# ATSAM3S1B device description
Architecture: CORTEX-M3; Family: SAM3; Series: SAM3S
Registers are 32-bit, read-write, no defined reset value unless marked. A register's access mark holds for its fields unless they carry their own. Offsets are from the block's base; [hi:lo] are bit positions; {n}, {i} and the like mark numbered series; 'fields as' and 'values as' point back to an identical list.

## USART — Universal Synchronous Asynchronous Receiver Transmitter
Instances: USART0 0x40024000, USART1 0x40028000
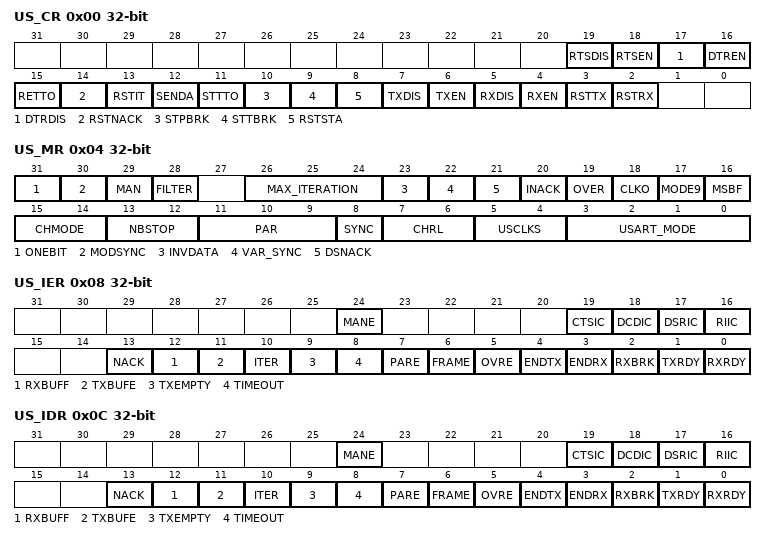
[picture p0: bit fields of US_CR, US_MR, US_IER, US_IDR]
0x00 US_CR wo — Control Register
  [19] RTSDIS — Request to Send Disable
  [18] RTSEN — Request to Send Enable
  [17] DTRDIS — Data Terminal Ready Disable
  [16] DTREN — Data Terminal Ready Enable
  [15] RETTO — Rearm Time-out
  [14] RSTNACK — Reset Non Acknowledge
  [13] RSTIT — Reset Iterations
  [12] SENDA — Send Address
  [11] STTTO — Start Time-out
  [10] STPBRK — Stop Break
  [9] STTBRK — Start Break
  [8] RSTSTA — Reset Status Bits
  [7] TXDIS — Transmitter Disable
  [6] TXEN — Transmitter Enable
  [5] RXDIS — Receiver Disable
  [4] RXEN — Receiver Enable
  [3] RSTTX — Reset Transmitter
  [2] RSTRX — Reset Receiver
0x04 US_MR — Mode Register
  [31] ONEBIT — Start Frame Delimiter Selector
  [30] MODSYNC — Manchester Synchronization Mode
  [29] MAN — Manchester Encoder/Decoder Enable
  [28] FILTER — Infrared Receive Line Filter
  [26:24] MAX_ITERATION — Maximum Number of Automatic Iteration
  [23] INVDATA — Inverted Data
  [22] VAR_SYNC — Variable Synchronization of Command/Data Sync Start Frame Delimiter
  [21] DSNACK — Disable Successive NACK
  [20] INACK — Inhibit Non Acknowledge
  [19] OVER — Oversampling Mode
  [18] CLKO — Clock Output Select
  [17] MODE9 — 9-bit Character Length
  [16] MSBF — Bit Order
  [15:14] CHMODE — Channel Mode
    0=NORMAL (Normal Mode); 1=AUTOMATIC (Automatic Echo. Receiver input is connected to the TXD pin.); 2=LOCAL_LOOPBACK (Local Loopback. Transmitter output is connected to the Receiver Input.); 3=REMOTE_LOOPBACK (Remote Loopback. RXD pin is internally connected to the TXD pin.)
  [13:12] NBSTOP — Number of Stop Bits
    0=_1_BIT (1 stop bit); 1=_1_5_BIT (1.5 stop bit (SYNC = 0) or reserved (SYNC = 1)); 2=_2_BIT (2 stop bits)
  [11:9] PAR — Parity Type
    0=EVEN (Even parity); 1=ODD (Odd parity); 2=SPACE (Parity forced to 0 (Space)); 3=MARK (Parity forced to 1 (Mark)); 4=NO (No parity); 6=MULTIDROP (Multidrop mode)
  [8] SYNC — Synchronous Mode Select
  [7:6] CHRL — Character Length.
    {v}=_{v+5}_BIT (Character length is {v+5} bits) (v=0..3)
  [5:4] USCLKS — Clock Selection
    0=MCK (Master Clock MCK is selected); 1=DIV (Internal Clock Divided MCK/DIV (DIV=8) is selected); 3=SCK (Serial Clock SLK is selected)
  [3:0] USART_MODE — USART Mode of Operation
    0=NORMAL (Normal mode); 1=RS485; 2=HW_HANDSHAKING (Hardware Handshaking); 3=MODEM; 4=IS07816_T_0 (IS07816 Protocol: T = 0); 6=IS07816_T_1 (IS07816 Protocol: T = 1); 8=IRDA; 14=SPI_MASTER; 15=SPI_SLAVE
0x08 US_IER wo — Interrupt Enable Register
  [24] MANE — Manchester Error Interrupt Enable
  [19] CTSIC — Clear to Send Input Change Interrupt Enable
  [18] DCDIC — Data Carrier Detect Input Change Interrupt Enable
  [17] DSRIC — Data Set Ready Input Change Enable
  [16] RIIC — Ring Indicator Input Change Enable
  [13] NACK — Non AcknowledgeInterrupt Enable
  [12] RXBUFF — Buffer Full Interrupt Enable (available in all USART modes of operation)
  [11] TXBUFE — Buffer Empty Interrupt Enable (available in all USART modes of operation)
  [10] ITER — Max number of Repetitions Reached Interrupt Enable
  [9] TXEMPTY — TXEMPTY Interrupt Enable
  [8] TIMEOUT — Time-out Interrupt Enable
  [7] PARE — Parity Error Interrupt Enable
  [6] FRAME — Framing Error Interrupt Enable
  [5] OVRE — Overrun Error Interrupt Enable
  [4] ENDTX — End of Transmit Interrupt Enable (available in all USART modes of operation)
  [3] ENDRX — End of Receive Transfer Interrupt Enable (available in all USART modes of operation)
  [2] RXBRK — Receiver Break Interrupt Enable
  [1] TXRDY — TXRDY Interrupt Enable
  [0] RXRDY — RXRDY Interrupt Enable
0x0C US_IDR wo — Interrupt Disable Register
  [24] MANE — Manchester Error Interrupt Disable
  [19] CTSIC — Clear to Send Input Change Interrupt Disable
  [18] DCDIC — Data Carrier Detect Input Change Interrupt Disable
  [17] DSRIC — Data Set Ready Input Change Disable
  [16] RIIC — Ring Indicator Input Change Disable
  [13] NACK — Non AcknowledgeInterrupt Disable
  [12] RXBUFF — Buffer Full Interrupt Disable (available in all USART modes of operation)
  [11] TXBUFE — Buffer Empty Interrupt Disable (available in all USART modes of operation)
  [10] ITER — Max Number of Repetitions Reached Interrupt Disable
  [9] TXEMPTY — TXEMPTY Interrupt Disable
  [8] TIMEOUT — Time-out Interrupt Disable
  [7] PARE — Parity Error Interrupt Disable
  [6] FRAME — Framing Error Interrupt Disable
  [5] OVRE — Overrun Error Interrupt Enable
  [4] ENDTX — End of Transmit Interrupt Disable (available in all USART modes of operation)
  [3] ENDRX — End of Receive Transfer Interrupt Disable (available in all USART modes of operation)
  [2] RXBRK — Receiver Break Interrupt Disable
  [1] TXRDY — TXRDY Interrupt Disable
  [0] RXRDY — RXRDY Interrupt Disable
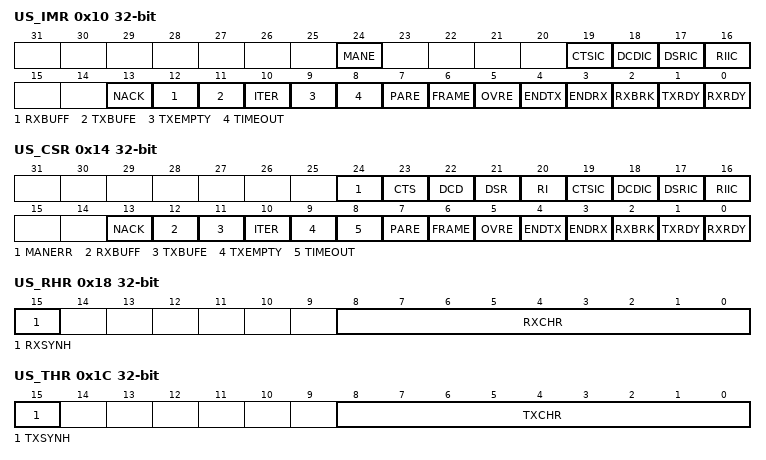
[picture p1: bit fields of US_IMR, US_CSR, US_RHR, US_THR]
0x10 US_IMR ro — Interrupt Mask Register
  [24] MANE — Manchester Error Interrupt Mask
  [19] CTSIC — Clear to Send Input Change Interrupt Mask
  [18] DCDIC — Data Carrier Detect Input Change Interrupt Mask
  [17] DSRIC — Data Set Ready Input Change Mask
  [16] RIIC — Ring Indicator Input Change Mask
  [13] NACK — Non AcknowledgeInterrupt Mask
  [12] RXBUFF — Buffer Full Interrupt Mask (available in all USART modes of operation)
  [11] TXBUFE — Buffer Empty Interrupt Mask (available in all USART modes of operation)
  [10] ITER — Max Number of Repetitions Reached Interrupt Mask
  [9] TXEMPTY — TXEMPTY Interrupt Mask
  [8] TIMEOUT — Time-out Interrupt Mask
  [7] PARE — Parity Error Interrupt Mask
  [6] FRAME — Framing Error Interrupt Mask
  [5] OVRE — Overrun Error Interrupt Mask
  [4] ENDTX — End of Transmit Interrupt Mask (available in all USART modes of operation)
  [3] ENDRX — End of Receive Transfer Interrupt Mask (available in all USART modes of operation)
  [2] RXBRK — Receiver Break Interrupt Mask
  [1] TXRDY — TXRDY Interrupt Mask
  [0] RXRDY — RXRDY Interrupt Mask
0x14 US_CSR ro — Channel Status Register
  [24] MANERR — Manchester Error
  [23] CTS — Image of CTS Input
  [22] DCD — Image of DCD Input
  [21] DSR — Image of DSR Input
  [20] RI — Image of RI Input
  [19] CTSIC — Clear to Send Input Change Flag
  [18] DCDIC — Data Carrier Detect Input Change Flag
  [17] DSRIC — Data Set Ready Input Change Flag
  [16] RIIC — Ring Indicator Input Change Flag
  [13] NACK — Non AcknowledgeInterrupt
  [12] RXBUFF — Reception Buffer Full
  [11] TXBUFE — Transmission Buffer Empty
  [10] ITER — Max Number of Repetitions Reached
  [9] TXEMPTY — Transmitter Empty
  [8] TIMEOUT — Receiver Time-out
  [7] PARE — Parity Error
  [6] FRAME — Framing Error
  [5] OVRE — Overrun Error
  [4] ENDTX — End of Transmitter Transfer
  [3] ENDRX — End of Receiver Transfer
  [2] RXBRK — Break Received/End of Break
  [1] TXRDY — Transmitter Ready
  [0] RXRDY — Receiver Ready
0x18 US_RHR ro — Receiver Holding Register
  [15] RXSYNH — Received Sync
  [8:0] RXCHR — Received Character
0x1C US_THR wo — Transmitter Holding Register
  [15] TXSYNH — Sync Field to be Transmitted
  [8:0] TXCHR — Character to be Transmitted
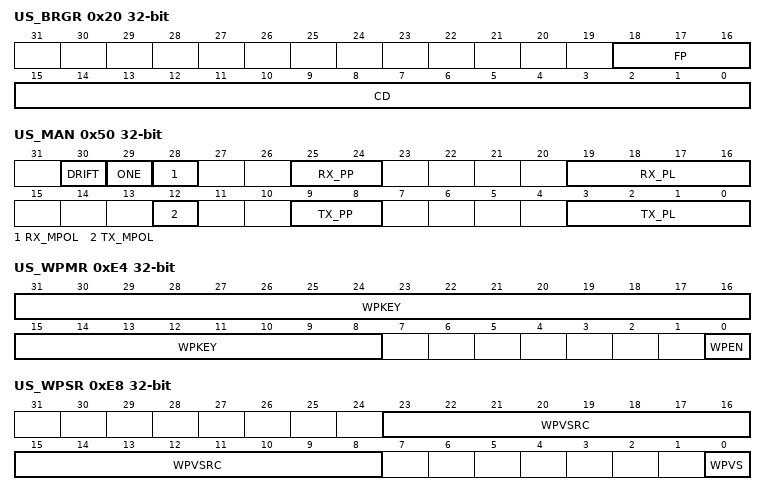
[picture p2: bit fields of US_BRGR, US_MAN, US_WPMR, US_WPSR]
0x20 US_BRGR — Baud Rate Generator Register
  [18:16] FP — Fractional Part
  [15:0] CD — Clock Divider
0x24 US_RTOR — Receiver Time-out Register
  [15:0] TO — Time-out Value
0x28 US_TTGR — Transmitter Timeguard Register
  [7:0] TG — Timeguard Value
0x40 US_FIDI — FI DI Ratio Register
  [15:0] FI_DI_RATIO — FI Over DI Ratio Value
0x44 US_NER ro — Number of Errors Register
  [7:0] NB_ERRORS — Number of Errors
0x4C US_IF — IrDA Filter Register
  [7:0] IRDA_FILTER
0x50 US_MAN — Manchester Encoder Decoder Register
  [30] DRIFT — Drift Compensation
  [29] ONE — Must Be Set to 1
  [28] RX_MPOL — Receiver Manchester Polarity
  [25:24] RX_PP — Receiver Preamble Pattern detected
    0=ALL_ONE (The preamble is composed of '1's); 1=ALL_ZERO (The preamble is composed of '0's); 2=ZERO_ONE (The preamble is composed of '01's); 3=ONE_ZERO (The preamble is composed of '10's)
  [19:16] RX_PL — Receiver Preamble Length
  [12] TX_MPOL — Transmitter Manchester Polarity
  [9:8] TX_PP — Transmitter Preamble Pattern
    values as RX_PP
  [3:0] TX_PL — Transmitter Preamble Length
0xE4 US_WPMR — Write Protect Mode Register
  [31:8] WPKEY — Write Protect KEY.
    0x555341=PASSWD (Writing any other value in this field aborts the write operation of the WPEN bit. Always reads as 0.)
  [0] WPEN — Write Protect Enable
0xE8 US_WPSR ro — Write Protect Status Register
  [23:8] WPVSRC — Write Protect Violation Source
  [0] WPVS — Write Protect Violation Status
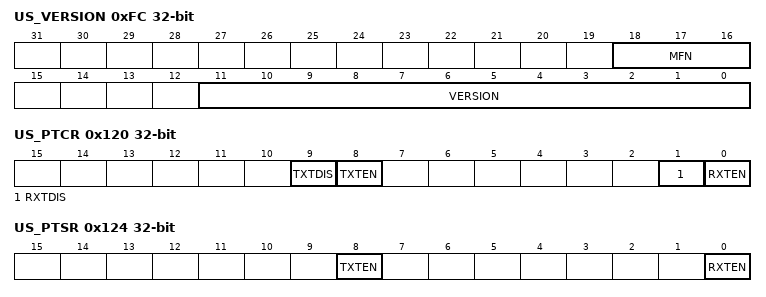
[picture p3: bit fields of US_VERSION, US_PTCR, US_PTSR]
0xFC US_VERSION ro — Version Register
  [18:16] MFN — Metal Fix Number
  [11:0] VERSION — Hardware Module Version
0x100 US_RPR — Receive Pointer Register
  [31:0] RXPTR
0x104 US_RCR — Receive Counter Register
  [15:0] RXCTR
0x108 US_TPR — Transmit Pointer Register
  [31:0] TXPTR — Transmit Counter Register
0x10C US_TCR — Transmit Counter Register
  [15:0] TXCTR
0x110 US_RNPR — Receive Next Pointer Register
  [31:0] RXNPTR — Receive Next Pointer
0x114 US_RNCR — Receive Next Counter Register
  [15:0] RXNCTR — Receive Next Counter
0x118 US_TNPR — Transmit Next Pointer Register
  [31:0] TXNPTR — Transmit Next Pointer
0x11C US_TNCR — Transmit Next Counter Register
  [15:0] TXNCTR — Transmit Counter Next
0x120 US_PTCR wo — Transfer Control Register
  [9] TXTDIS — Transmitter Transfer Disable
  [8] TXTEN — Transmitter Transfer Enable
  [1] RXTDIS — Receiver Transfer Disable
  [0] RXTEN — Receiver Transfer Enable
0x124 US_PTSR ro — Transfer Status Register
  [8] TXTEN — Transmitter Transfer Enable
  [0] RXTEN — Receiver Transfer Enable

## Notices in the file
SAM Software Package License
Copyright (c) %copyright_year%, Atmel Corporation
All rights reserved.
Redistribution and use in source and binary forms, with or without
modification, are permitted provided that the following condition is met:
- Redistributions of source code must retain the above copyright notice,
this list of conditions and the disclaimer below.
Atmel's name may not be used to endorse or promote products derived from
this software without specific prior written permission.
DISCLAIMER:  THIS SOFTWARE IS PROVIDED BY ATMEL "AS IS" AND ANY EXPRESS OR
IMPLIED WARRANTIES, INCLUDING, BUT NOT LIMITED TO, THE IMPLIED WARRANTIES OF
MERCHANTABILITY, FITNESS FOR A PARTICULAR PURPOSE AND NON-INFRINGEMENT ARE
DISCLAIMED. IN NO EVENT SHALL ATMEL BE LIABLE FOR ANY DIRECT, INDIRECT,
INCIDENTAL, SPECIAL, EXEMPLARY, OR CONSEQUENTIAL DAMAGES (INCLUDING, BUT NOT
LIMITED TO, PROCUREMENT OF SUBSTITUTE GOODS OR SERVICES; LOSS OF USE, DATA,
OR PROFITS; OR BUSINESS INTERRUPTION) HOWEVER CAUSED AND ON ANY THEORY OF
LIABILITY, WHETHER IN CONTRACT, STRICT LIABILITY, OR TORT (INCLUDING
NEGLIGENCE OR OTHERWISE) ARISING IN ANY WAY OUT OF THE USE OF THIS SOFTWARE,
EVEN IF ADVISED OF THE POSSIBILITY OF SUCH DAMAGE.
